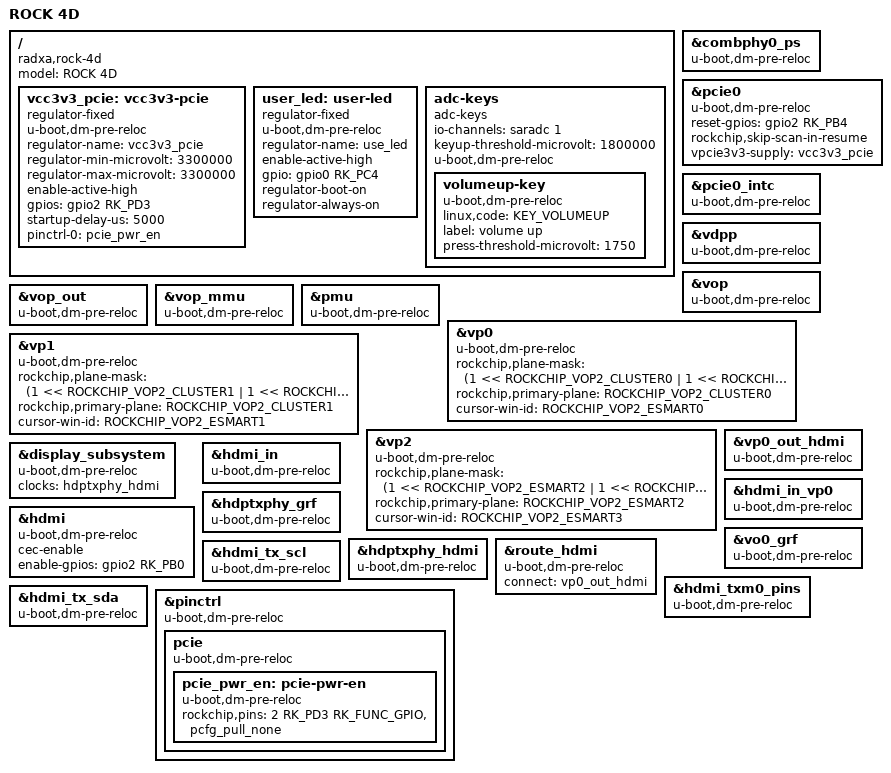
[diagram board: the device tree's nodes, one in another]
// SPDX-License-Identifier: (GPL-2.0+ OR MIT)
/*
 * Copyright (c) 2024 Rockchip Electronics Co., Ltd.
 * Copyright (c) 2024 Radxa Computer (Shenzhen) Co., Ltd.
 */

/dts-v1/;
#include "rk3576.dtsi"
#include "rk3576-u-boot.dtsi"
#include <dt-bindings/display/rockchip_vop.h>
#include <dt-bindings/gpio/gpio.h>
#include <dt-bindings/input/input.h>

/ {
	model = "ROCK 4D";
	compatible = "radxa,rock-4d", "rockchip,rk3576";

	vcc3v3_pcie: vcc3v3-pcie {
		u-boot,dm-pre-reloc;
		compatible = "regulator-fixed";
		regulator-name = "vcc3v3_pcie";
		regulator-min-microvolt = <3300000>;
		regulator-max-microvolt = <3300000>;
		enable-active-high;
		gpios = <&gpio2 RK_PD3 GPIO_ACTIVE_HIGH>;
		startup-delay-us = <5000>;
		pinctrl-names = "default";
		pinctrl-0 = <&pcie_pwr_en>;
	};

	user_led: user-led {
		u-boot,dm-pre-reloc;
		compatible = "regulator-fixed";
		regulator-name = "use_led";
		enable-active-high;
		gpio = <&gpio0 RK_PC4 GPIO_ACTIVE_HIGH>;
		regulator-boot-on;
		regulator-always-on;
	};

	adc-keys {
		compatible = "adc-keys";
		io-channels = <&saradc 1>;
		io-channel-names = "buttons";
		keyup-threshold-microvolt = <1800000>;
		u-boot,dm-pre-reloc;
		status = "okay";

		volumeup-key {
			u-boot,dm-pre-reloc;
			linux,code = <KEY_VOLUMEUP>;
			label = "volume up";
			press-threshold-microvolt = <1750>;
		};
	};
};

&combphy0_ps {
	u-boot,dm-pre-reloc;
	status = "okay";
};

&pcie0 {
	u-boot,dm-pre-reloc;
	reset-gpios = <&gpio2 RK_PB4 GPIO_ACTIVE_HIGH>;
	rockchip,skip-scan-in-resume;
	vpcie3v3-supply = <&vcc3v3_pcie>;
	status = "okay";
};

&pcie0_intc {
	u-boot,dm-pre-reloc;
};

&vdpp {
	u-boot,dm-pre-reloc;
	status = "okay";
};

&vop {
	u-boot,dm-pre-reloc;
	status = "okay";
};

&vop_out {
	u-boot,dm-pre-reloc;
};

&vop_mmu {
	u-boot,dm-pre-reloc;
	status = "okay";
};

&pmu {
	u-boot,dm-pre-reloc;
};

&vp0 {
	u-boot,dm-pre-reloc;
	rockchip,plane-mask = <(1 << ROCKCHIP_VOP2_CLUSTER0 | 1 << ROCKCHIP_VOP2_ESMART0)>;
	rockchip,primary-plane = <ROCKCHIP_VOP2_CLUSTER0>;
	cursor-win-id = <ROCKCHIP_VOP2_ESMART0>;
};

&vp1 {
	u-boot,dm-pre-reloc;
	rockchip,plane-mask = <(1 << ROCKCHIP_VOP2_CLUSTER1 | 1 << ROCKCHIP_VOP2_ESMART1)>;
	rockchip,primary-plane = <ROCKCHIP_VOP2_CLUSTER1>;
	cursor-win-id = <ROCKCHIP_VOP2_ESMART1>;
};

&vp2 {
	u-boot,dm-pre-reloc;
	rockchip,plane-mask = <(1 << ROCKCHIP_VOP2_ESMART2 | 1 << ROCKCHIP_VOP2_ESMART3)>;
	rockchip,primary-plane = <ROCKCHIP_VOP2_ESMART2>;
	cursor-win-id = <ROCKCHIP_VOP2_ESMART3>;
};

&vp0_out_hdmi {
	u-boot,dm-pre-reloc;
};

&display_subsystem {
	u-boot,dm-pre-reloc;
	status = "okay";
	clocks = <&hdptxphy_hdmi>;
	clock-names = "hdmi0_phy_pll";
};

&hdmi {
	u-boot,dm-pre-reloc;
	status = "okay";
	cec-enable;
	enable-gpios = <&gpio2 RK_PB0 GPIO_ACTIVE_HIGH>;
};

&hdmi_in {
	u-boot,dm-pre-reloc;
};

&hdmi_in_vp0 {
	u-boot,dm-pre-reloc;
	status = "okay";
};

&hdptxphy_grf {
	u-boot,dm-pre-reloc;
};

&vo0_grf {
	u-boot,dm-pre-reloc;
};

&hdptxphy_hdmi {
	u-boot,dm-pre-reloc;
	status = "okay";
};

&route_hdmi {
	u-boot,dm-pre-reloc;
	status = "okay";
	connect = <&vp0_out_hdmi>;
};

&hdmi_txm0_pins {
	u-boot,dm-pre-reloc;
};

&hdmi_tx_scl {
	u-boot,dm-pre-reloc;
};

&hdmi_tx_sda {
	u-boot,dm-pre-reloc;
};

&pinctrl {
	u-boot,dm-pre-reloc;
	pcie {
		u-boot,dm-pre-reloc;
		pcie_pwr_en: pcie-pwr-en {
			u-boot,dm-pre-reloc;
			rockchip,pins = <2 RK_PD3 RK_FUNC_GPIO &pcfg_pull_none>;
		};
	};
};
